# MPU_CM1 register map
Vendor: Texas Instruments
Peripheral module from a debugger description file (folder omap4460).
Registers are 32-bit, access per field, reset 0x0 unless marked. A register's access mark holds for its fields unless they carry their own. Offsets are as the file gives them; lines under a group give offsets from that group; [hi:lo] are bit positions; {n}, {i} and the like mark numbered series; 'fields as' and 'values as' point back to an identical list; <NAME> marks a mode.

## MPU_CM1
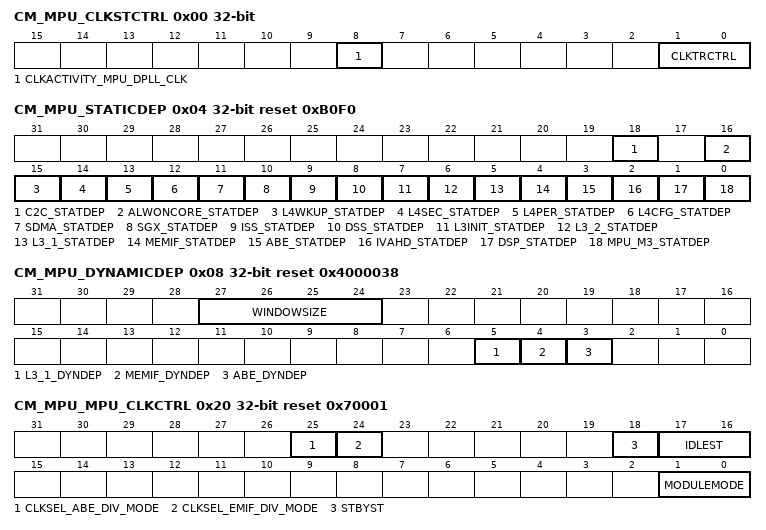
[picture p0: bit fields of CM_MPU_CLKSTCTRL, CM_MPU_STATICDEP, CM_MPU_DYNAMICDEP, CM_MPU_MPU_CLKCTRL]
0x00 CM_MPU_CLKSTCTRL — This register enables the MPU domain power state transition. It controls the hardware supervised domain power state transition between ON-ACTIVE and ON-INACTIVE states. It also holds 1 status bit per clock input of the domain.
  [8] CLKACTIVITY_MPU_DPLL_CLK ro — This field indicates the state of the MPU_DPLL_CLK clock in the domain. [warm reset insensitive]
    0=CLKACTIVITY_MPU_DPLL_CLK_0_r (Corresponding clock is definitely gated); 1=CLKACTIVITY_MPU_DPLL_CLK_1_r (Corresponding clock is running or gating/ungating transition is ongoing)
  [1:0] CLKTRCTRL rw — Controls the clock state transition of the MPU clock domain.
    0=NO_SLEEP: Sleep transition cannot be initiated. Wakeup transition may however occur.; 1=CLKTRCTRL_1_r (Reserved); 2=SW_WKUP: Start a software forced wake-up transition on the domain; 3=HW_AUTO: Automatic transition is enabled. Sleep and wakeup transition are based upon hardware conditions.
0x04 CM_MPU_STATICDEP reset 0xB0F0 — This register controls the static domain dependencies from MPU domain towards 'target' domains. It is relevant only for domain having system initiator(s).
  [18] C2C_STATDEP ro — Static dependency towards C2C clock domain
    0=C2C_STATDEP_0_r (Dependency is disabled)
  [16] ALWONCORE_STATDEP ro — Static dependency towards ALWONCORE clock domain
    0=ALWONCORE_STATDEP_0_r (Dependency is disabled)
  [15] L4WKUP_STATDEP rw — Static dependency towards L4WKUP clock domain
    0=Dependency is disabled; 1=Dependency is enabled
  [14] L4SEC_STATDEP rw — Static dependency towards L4SEC clock domain
    0=Dependency is disabled; 1=Dependency is enabled
  [13] L4PER_STATDEP rw — Static dependency towards L4PER clock domain
    0=Dependency is disabled; 1=Dependency is enabled
  [12] L4CFG_STATDEP rw — Static dependency towards L4CFG clock domain
    0=Dependency is disabled; 1=Dependency is enabled
  [11] SDMA_STATDEP ro — Static dependency towards SDMA clock domain
    0=SDMA_STATDEP_0_r (Dependency is disabled)
  [10] SGX_STATDEP rw — Static dependency towards SGX clock domain
    0=Dependency is disabled; 1=Dependency is enabled
  [9] ISS_STATDEP ro — Static dependency towards ISS clock domain
    0=ISS_STATDEP_0_r (Dependency is disabled)
  [8] DSS_STATDEP rw — Static dependency towards DSS clock domain
    0=Dependency is disabled; 1=Dependency is enabled
  [7] L3INIT_STATDEP rw — Static dependency towards L3INIT clock domain
    0=Dependency is disabled; 1=Dependency is enabled
  [6] L3_2_STATDEP rw — Static dependency towards L3_2 clock domain
    0=Dependency is disabled; 1=Dependency is enabled
  [5] L3_1_STATDEP rw — Static dependency towards L3_1 clock domain
    0=Dependency is disabled; 1=Dependency is enabled
  [4] MEMIF_STATDEP rw — Static dependency towards MEMIF clock domain
    0=Dependency is disabled; 1=Dependency is enabled
  [3] ABE_STATDEP rw — Static dependency towards ABE clock domain
    0=Dependency is disabled; 1=Dependency is enabled
  [2] IVAHD_STATDEP rw — Static dependency towards IVAHD clock domain
    0=Dependency is disabled; 1=Dependency is enabled
  [1] DSP_STATDEP rw — Static dependency towards DSP clock domain
    0=Dependency is disabled; 1=Dependency is enabled
  [0] MPU_M3_STATDEP rw — Static dependency towards MPU_A3 clock domain
    0=Dependency is disabled; 1=Dependency is enabled
0x08 CM_MPU_DYNAMICDEP access not given reset 0x4000038 — This register controls the dynamic domain depedencies from MPU domain towards 'target' domains. It is relevant only for domain having INTRCONN master port(s).
  [27:24] WINDOWSIZE rw — Size of sliding window used to monitor INTRCONN interface activity for determination of auto-sleep feature. Time unit defined byCM_DYN_DEP_PRESCAL register.
  [5] L3_1_DYNDEP — Dynamic dependency towards L3_1 clock domain (access R Rreturns1s)
    1=L3_1_DYNDEP_1_r (Dependency is enabled)
  [4] MEMIF_DYNDEP — Dynamic dependency towards MEMIF clock domain (access R Rreturns1s)
    1=MEMIF_DYNDEP_1_r (Dependency is enabled)
  [3] ABE_DYNDEP — Dynamic dependency towards ABE clock domain (access R Rreturns1s)
    1=ABE_DYNDEP_1_r (Dependency is enabled)
0x20 CM_MPU_MPU_CLKCTRL access not given reset 0x70001 — This register manages the MPU clocks.
  [25] CLKSEL_ABE_DIV_MODE rw — Selects the ratio for MPU-ABE async bridge versus MPU DPLL clock.
    0=MPU DPLL clock divided by 4; 1=MPU DPLL clock divided by 8
  [24] CLKSEL_EMIF_DIV_MODE rw — Selects the ratio for memory adapter clock (MA_EOCP_ICLK) versus MPU DPLL clock.
    0=MPU DPLL clock divided by 2; 1=MPU DPLL clock divided by 4
  [18] STBYST ro — Module standby status. [warm reset insensitive]
    0=STBYST_0_r (Module is functional (not in standby)); 1=STBYST_1_r (Module is in standby)
  [17:16] IDLEST ro — Module idle status. [warm reset insensitive]
    0=IDLEST_0_r (Module is fully functional, including INTRCONN); 1=IDLEST_1_r (Module is performing transition: wakeup, or sleep, or sleep abortion); 2=IDLEST_2_r (Module is in Idle mode (only INTRCONN part). It is functional if using separate functional clock); 3=IDLEST_3_r (Module is disabled and cannot be accessed)
  [1:0] MODULEMODE — Control the way mandatory clocks are managed. (access R Rreturns)
    1=MODULEMODE_1_r (Module is managed automatically by hardware according to clock domain transition. A clock domain sleep transition put module into idle. A wakeup domain transition put it back into function. Module clocks may be gated according to the clock domain state.)
